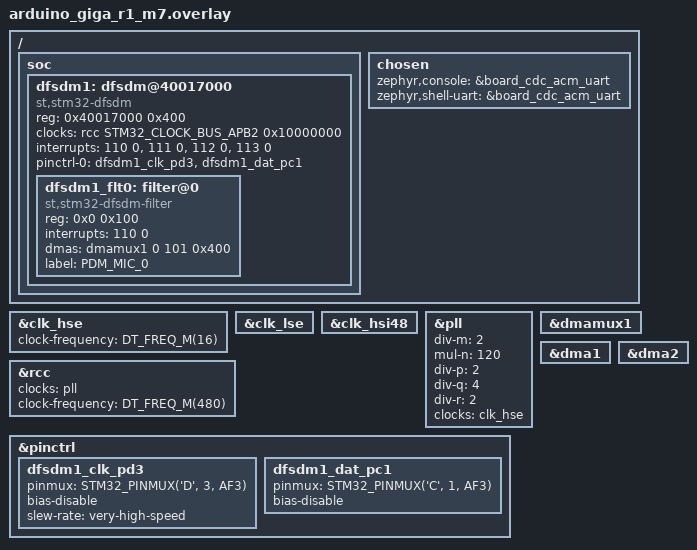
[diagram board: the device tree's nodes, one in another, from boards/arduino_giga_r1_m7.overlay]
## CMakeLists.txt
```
# samples/drivers/dfsdm_microphone/CMakeLists.txt

cmake_minimum_required(VERSION 3.20.0)

# 1. Pull in the Zephyr Build System
find_package(Zephyr REQUIRED HINTS $ENV{ZEPHYR_BASE})

# 2. Define the project name
project(dfsdm_microphone)

# 3. Add your source file(s) to the 'app' target
target_sources(app PRIVATE src/main.c)
```

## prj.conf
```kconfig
CONFIG_DFSDM_STM32=y
CONFIG_GPIO=y
CONFIG_DMA=y
CONFIG_DFSDM=y
CONFIG_LOG=y
CONFIG_DFSDM_LOG_LEVEL_DBG=y

# --- Legacy USB Stack Settings ---
CONFIG_USB_DEVICE_STACK=y
CONFIG_USB_DEVICE_PRODUCT="Zephyr CDC ACM Console"

# --- Serial Console Settings ---
CONFIG_SERIAL=y
CONFIG_CONSOLE=y
CONFIG_UART_CONSOLE=y
CONFIG_UART_LINE_CTRL=y
CONFIG_STDOUT_CONSOLE=y

# --- THE FIX: Disable the New Stack ---
# The Giga R1 enables these by default in Zephyr 4.3.
# We must disable them to avoid "Multiple Definition" errors.
CONFIG_USB_DEVICE_STACK_NEXT=n
CONFIG_USB_DEVICE_DRIVER=n
CONFIG_CLOCK_CONTROL=y
CONFIG_CLOCK_CONTROL_STM32_CUBE=y


CONFIG_DEBUG=y
CONFIG_DEBUG_OPTIMIZATIONS=y
CONFIG_DEBUG_THREAD_INFO=y
CONFIG_STACK_SENTINEL=y

CONFIG_BOOT_BANNER=n
```

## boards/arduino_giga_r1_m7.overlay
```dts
#include <zephyr/dt-bindings/clock/stm32h7_clock.h>
#include <zephyr/dt-bindings/pinctrl/stm32-pinctrl.h>


/* * PART 1: Define the Missing Hardware Node
 * We use the path "/ { soc { ... } }" instead of "&soc" to be safe.
 */
/ {
    soc {
        dfsdm1: dfsdm@40017000 {
            compatible = "st,stm32-dfsdm";
            reg = <0x40017000 0x400>; /* 1KB register space */

	    /* bit 28 enable DFSDM */
            clocks = <&rcc STM32_CLOCK_BUS_APB2 0x10000000>;

            interrupts = <110 0>, <111 0>, <112 0>, <113 0>;
            interrupt-names = "flt0", "flt1", "flt2", "flt3";

            #address-cells = <1>;
            #size-cells = <1>;

            status = "disabled";
        };
    };

    /* USB */
    chosen {
	zephyr,console = &board_cdc_acm_uart;
	zephyr,shell-uart = &board_cdc_acm_uart;
    };
};


&clk_hse {
	status = "okay";
	clock-frequency = <DT_FREQ_M(16)>;
};

&clk_lse {
	status = "okay";
};

&clk_hsi48 {
	status = "okay";
};

&pll {
	div-m = <2>;
	mul-n = <120>;
	div-p = <2>;
	div-q = <4>;
	div-r = <2>;
	clocks = <&clk_hse>;
	status = "okay";
};

&rcc {
	clocks = <&pll>;
	clock-frequency = <DT_FREQ_M(480)>;
};

&pinctrl {
    dfsdm1_clk_pd3: dfsdm1_clk_pd3 {
        pinmux = <STM32_PINMUX('D', 3, AF3)>; /* DFSDM1_CKOUT */
        bias-disable;
        slew-rate = "very-high-speed";
    };

    dfsdm1_dat_pc1: dfsdm1_dat_pc1 {
        pinmux = <STM32_PINMUX('C', 1, AF3)>; /* DFSDM1_DATIN0 */
        bias-disable;
    };
};

&dfsdm1 {
    status = "okay";
    pinctrl-0 = <&dfsdm1_clk_pd3 &dfsdm1_dat_pc1>;
    pinctrl-names = "default";

    /* Define the specific filter we want to use */
    dfsdm1_flt0: filter@0 {
        compatible = "st,stm32-dfsdm-filter";
        reg = <0x0 0x100>; /* Offset 0 for FLT0 */

        interrupts = <110 0>;

        /* DMA Config for H7 (DMAMUX)
         * Request 101 = DFSDM1_FLT0
         */
        dmas = <&dmamux1 0 101 0x400>;
        dma-names = "rx";

        status = "okay";
        label = "PDM_MIC_0";
    };
};

/* Enable the DMA Multiplexer */
&dmamux1 {
	    status = "okay";
};

/* Enable the underlying DMA controllers (if not already enabled by board) */
&dma1 {
	    status = "okay";
};

&dma2 {
	    status = "okay";
};
```

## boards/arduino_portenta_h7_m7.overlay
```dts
#include <zephyr/dt-bindings/clock/stm32_clock.h>
#include <zephyr/dt-bindings/pinctrl/stm32-pinctrl.h>

/* * PART 1: Define the Missing Hardware Node
 * We use the path "/ { soc { ... } }" instead of "&soc" to be safe.
 */
/ {
    soc {
        dfsdm1: dfsdm@40017000 {
            compatible = "st,stm32-dfsdm";
            reg = <0x40017000 0x400>; /* 1KB register space */

            /* Bus: APB2, Bit: 0x40 (Bit 6 = DFSDM1EN) */
            clocks = <&rcc STM32_CLOCK_BUS_APB2 0x00000040>;

            interrupts = <110 0>, <111 0>, <112 0>, <113 0>;
            interrupt-names = "flt0", "flt1", "flt2", "flt3";

            #address-cells = <1>;
            #size-cells = <1>;

            status = "disabled";
        };
    };
};

/* * PART 2: Configure Pins
 */
&pinctrl {
    /* * NOTE: These are Example Pins (PE9/PE7).
     * On Arduino Portenta H7:
     * - You usually access pins via the high-density headers.
     * - Ensure these pins are not used by other onboard features (WiFi/Video).
     * - If you use different pins, change the 'pinmux' values below.
     */
    dfsdm1_clk_pe9: dfsdm1_clk_pe9 {
        pinmux = <STM32_PINMUX('E', 9, AF10)>; /* DFSDM1_CKOUT */
        bias-disable;
        slew-rate = "very-high-speed";
    };

    dfsdm1_dat_pe7: dfsdm1_dat_pe7 {
        pinmux = <STM32_PINMUX('E', 7, AF10)>; /* DFSDM1_DATIN2 */
        bias-disable;
    };
};

/* * PART 3: Enable and Configure the Peripheral
 */
&dfsdm1 {
    status = "okay";
    pinctrl-0 = <&dfsdm1_clk_pe9 &dfsdm1_dat_pe7>;
    pinctrl-names = "default";

    /* Define the specific filter we want to use */
    dfsdm1_flt0: filter@0 {
        compatible = "st,stm32-dfsdm-filter";
        reg = <0x0 0x100>; /* Offset 0 for FLT0 */

        interrupts = <110 0>;

        /* DMA Config for H7 (DMAMUX)
         * Request 101 = DFSDM1_FLT0
         */
        dmas = <&dmamux1 0 101 0x400>;
        dma-names = "rx";

        status = "okay";
        label = "PDM_MIC_0";
    };
};

/* Enable the DMA Multiplexer */
&dmamux1 {
	    status = "okay";
};

/* Enable the underlying DMA controllers (if not already enabled by board) */
&dma1 {
	    status = "okay";
};

&dma2 {
	    status = "okay";
};
```

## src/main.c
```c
/*
 * Copyright (c) 2026 Arduino (Daniele Aimo)
 * SPDX-License-Identifier: Apache-2.0
 */

#include <zephyr/device.h>
#include <zephyr/drivers/dfsdm.h>
#include <zephyr/kernel.h>
#include <zephyr/logging/log.h>

#include <zephyr/sys/printk.h>
#include <zephyr/usb/usb_device.h>
#include <zephyr/drivers/uart.h>
#include <zephyr/cache.h>

/* CONFIGURATION */

/* This example outputs the data obtained from the filter on the UART
 * if SAVE_RAW_DATA is NOT defined the data are printed in a human readable from
 * allowing to "see" the change while noises are recorded by the microphone
 *
 * if SAVE_RAW_DATA is defined the data are printed in order to be actually stored
 * in a wav play and listened */

#define SAVE_RAW_DATA

LOG_MODULE_REGISTER(main);

/* Get the device pointer from Device Tree */
const struct device *pdm_dev = DEVICE_DT_GET(DT_NODELABEL(dfsdm1_flt0));

/* Audio Configuration */
#define AUDIO_FREQ   16000
#define OVERSAMPLING 125
#define CLOCK_RATE   (AUDIO_FREQ * OVERSAMPLING) /* 2.0 MHz */

/* _____________________________________________________________________KSLAB */
#define BLOCK_SIZE_SAMPLES 256 /* ~16ms at 2MHz  */
#define BLOCK_SIZE_BYTES   (BLOCK_SIZE_SAMPLES * sizeof(int32_t))
#define BLOCK_NUM          2
#define DRIVE_BUFFER_SIZE  (BLOCK_SIZE_BYTES * BLOCK_NUM)
/* The driver will use this buffer to store samples from the filter
 * data are 32 aligned to allow cache invalidation */
int32_t __aligned(32) driver_data_buffer[BLOCK_SIZE_SAMPLES * BLOCK_NUM];

/* _________________________________________________________________SEMAPHORE */
/* Used to synchronize the main thread waiting for filtered data */
K_SEM_DEFINE(data_ready_sem, 0, 1);

/* Some quick facts:
 * - audio frequency 16000 Hz means 16000 sample per seconds
 * - a block of 256 sample is filled in 16 ms
 * - this means that the audio callback is called every 16 ms with 256 sample
 *   to be processed
 * - if the main loop is not faster than 16 ms data become corrupted and sample
 *   are lost or overwritten
 * - Setting USB Serial communication to 921600 BAUD means that printing 512 bytes
 *   (because we are squeezing 32 bit sample in 16 bit sample) would take around
 *   5.6 ms to print the buffer -> fast enough respect to the irq firing */

/* _____________________________________________________________DOUBLE_BUFFER */
/* Simply double buffer to "ping pong" data from device to application */
#define DOUBLE_BUFFER_SIZE BLOCK_SIZE_SAMPLES
int32_t double_buffer[2][DOUBLE_BUFFER_SIZE];
uint8_t current_buffer = 0;
#define INCREMENT(x, n)  x = (++x) % n
#define FILLED_BUFFER(n) ((n == 0) ? 1 : 0)

static volatile uint32_t received = 0;

/* ____________________________________________________________AUDIO CALLBACK */
/* It is called when a block of data is available
 * IMPORTANT: the callback is called in a IRQ context, it must perform operation
 * in the quickest possible way (in this case just copy received data for later
 * processing) */
void audio_callback(const struct device *dev, uint8_t filter_id, void *data, size_t size,
		    void *user_data)
{
	int32_t *samples = (int32_t *)data;
	/* copy data on user buffer */
	memcpy(double_buffer[current_buffer], samples, size);
	/* prepare for next chunck of data */
	INCREMENT(current_buffer, 2);
	/* tell the main thread data are ready */
	k_sem_give(&data_ready_sem);
	received += 1;
	// printk("%i\n", received);
}

/* This function is used to print a buffer on USB serial */
void uart_print(const struct device *dev, const char *buf)
{
	while (*buf) {
		uart_poll_out(dev, *buf);
		buf++;
	}
}

#ifdef SAVE_RAW_DATA

static int16_t print_binary_data[DOUBLE_BUFFER_SIZE];
/* This function prints raw data. If correctly saved in a wav file this can be
 * actually listened
 * To produce a wav file we use a simple python script which is expecting 2 bytes
 * per sample, but the filter is producing 32 bit wide data so first we "squeeze"
 * data into 16 bit per sample and then we print the whole new array in "raw"
 * format */
void uart_out(const struct device *dev, int32_t *buf, size_t dim)
{
	if (dim != DOUBLE_BUFFER_SIZE) {
		printk("Something wrong with sizes\n");
		return;
	}
	/* "squeeze data" */
	for (uint32_t i = 0; i < dim; i++) {
		print_binary_data[i] = (int16_t)(*(buf + i));
	}
	/* print raw data */
	unsigned char *b = (unsigned char *)print_binary_data;
	for (int i = 0; i < 256 * sizeof(int16_t); i++) {
		uart_poll_out(dev, *(b + i));
	}
}
#else
static int16_t print_binary_data[DOUBLE_BUFFER_SIZE];
void uart_out(const struct device *dev, int32_t *buf, size_t dim)
{
	char line_buf[16];
	if (dim != DOUBLE_BUFFER_SIZE) {
		printk("Something wrong with sizes\n");
		return;
	}
	/* "squeeze data" */
	char *b = line_buf;
	for (uint32_t i = 0; i < dim; i++) {
		print_binary_data[i] = (int16_t)(*(buf + i));
		snprintf(line_buf, sizeof(line_buf), "%i\n", print_binary_data[i]);
		while (*b) {
			uart_poll_out(dev, *b);
			b++;
		}
	}
}
#endif

/* This function is used to increase baurate of usb serial port */
void configure_usb_baudrate(const struct device *uart_dev)
{
	int ret;

	// Set the baudrate to 921600
	ret = uart_line_ctrl_set(uart_dev, UART_LINE_CTRL_BAUD_RATE, 921600);

	if (ret == -ENOSYS) {
		// This means the specific driver doesn't support setting baudrate manually
		printk("Baudrate setting not supported by this USB driver.\n");
	} else if (ret < 0) {
		printk("Error setting baudrate: %d\n", ret);
	} else {
		// printk("Baudrate set successfully!\n");
	}
}

int main(void)
{
	int err;

	const struct device *uart_dev = DEVICE_DT_GET(DT_CHOSEN(zephyr_console));
	uint32_t dtr = 0;

	/* Enable the USB Driver */
	if (usb_enable(NULL)) {
		return 0;
	}

	/* Wait for the host (PC) to connect to the Serial Port */
	while (!dtr) {
		uart_line_ctrl_get(uart_dev, UART_LINE_CTRL_DTR, &dtr);
		k_sleep(K_MSEC(100));
	}
	configure_usb_baudrate(uart_dev);

	/* ---- CHANNEL CONFIGURATION ---- */
	struct dfsdm_channel_config ch_cfg = {
		.channel_id = 0,
		.source = DFSDM_SOURCE_PIN,
		.type = DFSDM_TYPE_SPI_RISING,
		.clock_mode = DFSDM_CLOCK_INTERNAL,
		.clock_source = DFSDM_INT_CLOCK_SOURCE_0,
		.output_clock_rate = CLOCK_RATE,
		.offset = 0,
		.right_bit_shift = 0,
	};

	err = dfsdm_configure_channel(pdm_dev, &ch_cfg);

	if (err) {
		LOG_ERR("Failed to configure channel (err %d)", err);
		return err;
	}

	/* ----- STREAM CONFIGURATION (fiter settings) */

	struct dfsdm_stream_config stream_cfg = {
		.filter =
			{
				.filter_id = 0,
				.channel_id = 0,
				.sinc_type = DFSDM_SINC_FAST,
				.oversampling = OVERSAMPLING,
				.integrator = 0,
			},

		.data_buffer = driver_data_buffer,
		.data_buffer_size = DRIVE_BUFFER_SIZE,
		.invalidate_cache = true,
		.discard_first_n_block = 1,
		.callback = audio_callback,
		.user_data = NULL,
	};

	err = dfsdm_configure_stream(pdm_dev, &stream_cfg);

	if (err) {
		LOG_ERR("Failed to configure stream (err %d)", err);
		return err;
	}

	/* ------ START RECORDING ------ */

	err = dfsdm_trigger(pdm_dev, 0, DFSDM_TRIGGER_START);
	if (err) {
		LOG_ERR("Failed to trigger start (err %d)", err);
		return err;
	}
	/* ------ MAIN LOOP -------- */
	while (1) {
		/* Check connection status periodically */
		uart_line_ctrl_get(uart_dev, UART_LINE_CTRL_DTR, &dtr);

		if (dtr) {
			if (k_sem_take(&data_ready_sem, K_FOREVER) == 0) {

				if (received) {
					if (received > 1) {
						// printk("!!!!!!! MISSING DATA !!!!!!!\n\n");
					}
					received = 0;
					/* which buffer is full ? */
					uint8_t bi = FILLED_BUFFER(current_buffer);
					uart_out(uart_dev, (const char *)double_buffer[bi],
						 DOUBLE_BUFFER_SIZE);
				}
			}
		} else {
			k_sem_reset(&data_ready_sem);
			k_sleep(K_MSEC(100));
		}
	}

	return 0;
}
```
